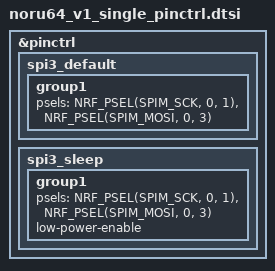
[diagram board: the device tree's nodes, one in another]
/*
 * Copyright (c) 2020 Eric Lau
 *
 * SPDX-License-Identifier: MIT
 */

&pinctrl {
    spi3_default: spi3_default {
        group1 {
            psels = <NRF_PSEL(SPIM_SCK, 0, 1)>,
                    <NRF_PSEL(SPIM_MOSI, 0, 3)>;
        };
    };

    spi3_sleep: spi3_sleep {
        group1 {
            psels = <NRF_PSEL(SPIM_SCK, 0, 1)>,
                    <NRF_PSEL(SPIM_MOSI, 0, 3)>;
            low-power-enable;
        };
    };
};
